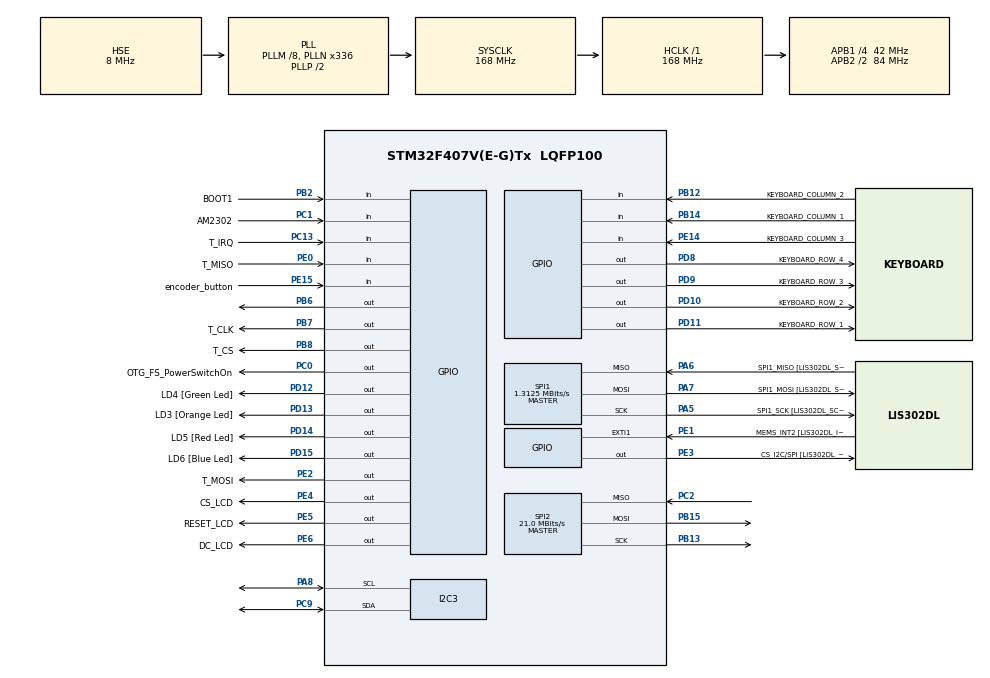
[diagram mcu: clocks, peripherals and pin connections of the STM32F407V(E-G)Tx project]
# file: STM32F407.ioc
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Mcu.Family=STM32F4
Mcu.Name=STM32F407V(E-G)Tx
Mcu.Package=LQFP100
NVIC.PriorityGroup=NVIC_PRIORITYGROUP_0
NVIC.RCC_IRQn=true\:0\:0\:false\:false\:true\:true\:false
NVIC.TIM1_CC_IRQn=true\:0\:0\:false\:false\:true\:true\:true
PA11.GPIO_Label=OTG_FS_DM
PA11.GPIO_Mode=GPIO_MODE_AF_PP
PA11.GPIO_PuPd=GPIO_NOPULL
PA11.GPIO_Speed=GPIO_SPEED_FREQ_LOW
PA11.Signal=USB_OTG_FS_DM
PA13.GPIO_Label=SWDIO
PA13.Mode=Serial_Wire
PA13.Signal=SYS_JTMS-SWDIO
PA14.GPIO_Label=SWCLK
PA14.Mode=Serial_Wire
PA14.Signal=SYS_JTCK-SWCLK
PA4.GPIO_Label=I2S3_WS [CS43L22_LRCK]
PA4.GPIO_Mode=GPIO_MODE_AF_PP
PA4.GPIO_PuPd=GPIO_NOPULL
PA4.GPIO_Speed=GPIO_SPEED_FREQ_LOW
PA4.Signal=I2S3_WS
PA5.GPIO_Label=SPI1_SCK [LIS302DL_SCL/SPC]
PA5.GPIO_Mode=GPIO_MODE_AF_PP
PA5.GPIO_PuPd=GPIO_NOPULL
PA5.GPIO_Speed=GPIO_SPEED_FREQ_VERY_HIGH
PA5.Mode=Full_Duplex_Master
PA5.Signal=SPI1_SCK
PA6.GPIO_Label=SPI1_MISO [LIS302DL_SDO]
PA6.GPIO_Mode=GPIO_MODE_AF_PP
PA6.GPIO_PuPd=GPIO_NOPULL
PA6.GPIO_Speed=GPIO_SPEED_FREQ_VERY_HIGH
PA6.Mode=Full_Duplex_Master
PA6.Signal=SPI1_MISO
PA7.GPIO_Label=SPI1_MOSI [LIS302DL_SDA/SDI/SDO]
PA7.GPIO_Mode=GPIO_MODE_AF_PP
PA7.GPIO_PuPd=GPIO_NOPULL
PA7.GPIO_Speed=GPIO_SPEED_FREQ_VERY_HIGH
PA7.Mode=Full_Duplex_Master
PA7.Signal=SPI1_MOSI
PA8.Mode=I2C
PA8.Signal=I2C3_SCL
PA9.GPIO_Label=VBUS_FS
PA9.GPIO_Mode=GPIO_MODE_INPUT
PA9.GPIO_PuPd=GPIO_NOPULL
PA9.Signal=USB_OTG_FS_VBUS
PB12.GPIO_Label=KEYBOARD_COLUMN_2
PB12.GPIO_PuPd=GPIO_PULLUP
PB12.Signal=GPIO_Input
PB13.Mode=Full_Duplex_Master
PB13.Signal=SPI2_SCK
PB14.GPIO_Label=KEYBOARD_COLUMN_1
PB14.GPIO_PuPd=GPIO_PULLUP
PB14.Signal=GPIO_Input
PB15.Mode=Full_Duplex_Master
PB15.Signal=SPI2_MOSI
PB2.GPIO_Label=BOOT1
PB2.GPIO_Mode=GPIO_MODE_INPUT
PB2.GPIO_PuPd=GPIO_NOPULL
PB2.Signal=GPIO_Input
PB3.GPIO_Label=SWO
PB3.Signal=SYS_JTDO-SWO
PB6.Signal=GPIO_Output
PB7.GPIO_Label=T_CLK
PB7.GPIO_Speed=GPIO_SPEED_FREQ_VERY_HIGH
PB7.Signal=GPIO_Output
PB8.GPIO_Label=T_CS
PB8.GPIO_Speed=GPIO_SPEED_FREQ_VERY_HIGH
PB8.Signal=GPIO_Output
PB9.GPIO_Label=Audio_SDA [CS43L22_SDA]
PB9.GPIO_Mode=GPIO_MODE_AF_OD
PB9.GPIO_PuPd=GPIO_NOPULL
PB9.GPIO_Speed=GPIO_SPEED_FREQ_LOW
PB9.Signal=I2C1_SDA
PC0.GPIO_Label=OTG_FS_PowerSwitchOn
PC0.GPIO_PuPd=GPIO_NOPULL
PC0.GPIO_Speed=GPIO_SPEED_FREQ_LOW
PC0.PinState=GPIO_PIN_SET
PC0.Signal=GPIO_Output
PC1.GPIO_Label=AM2302
PC1.Signal=GPIO_Input
PC13-ANTI_TAMP.GPIO_Label=T_IRQ
PC13-ANTI_TAMP.Signal=GPIO_Input
PC14-OSC32_IN.GPIO_Label=PC14-OSC32_IN
PC14-OSC32_IN.Mode=LSE-External-Oscillator
PC14-OSC32_IN.Signal=RCC_OSC32_IN
PC15-OSC32_OUT.GPIO_Label=PC15-OSC32_OUT
PC15-OSC32_OUT.Mode=LSE-External-Oscillator
PC15-OSC32_OUT.Signal=RCC_OSC32_OUT
PC2.Mode=Full_Duplex_Master
PC2.Signal=SPI2_MISO
PC3.GPIO_Label=PDM_OUT [MP45DT02_DOUT]
PC3.GPIO_Mode=GPIO_MODE_AF_PP
PC3.GPIO_PuPd=GPIO_NOPULL
PC3.GPIO_Speed=GPIO_SPEED_FREQ_LOW
PC3.Signal=I2S2_SD
PC9.Mode=I2C
PC9.Signal=I2C3_SDA
PD10.GPIO_Label=KEYBOARD_ROW_2
PD10.PinState=GPIO_PIN_RESET
PD10.Signal=GPIO_Output
PD11.GPIO_Label=KEYBOARD_ROW_1
PD11.PinState=GPIO_PIN_RESET
PD11.Signal=GPIO_Output
PD12.GPIO_Label=LD4 [Green Led]
PD12.GPIO_PuPd=GPIO_NOPULL
PD12.GPIO_Speed=GPIO_SPEED_FREQ_LOW
PD12.Signal=GPIO_Output
PD13.GPIO_Label=LD3 [Orange Led]
PD13.GPIO_PuPd=GPIO_NOPULL
PD13.GPIO_Speed=GPIO_SPEED_FREQ_LOW
PD13.Signal=GPIO_Output
PD14.GPIO_Label=LD5 [Red Led]
PD14.GPIO_PuPd=GPIO_NOPULL
PD14.GPIO_Speed=GPIO_SPEED_FREQ_LOW
PD14.Signal=GPIO_Output
PD15.GPIO_Label=LD6 [Blue Led]
PD15.GPIO_PuPd=GPIO_NOPULL
PD15.GPIO_Speed=GPIO_SPEED_FREQ_LOW
PD15.Signal=GPIO_Output
PD8.GPIO_Label=KEYBOARD_ROW_4
PD8.PinState=GPIO_PIN_RESET
PD8.Signal=GPIO_Output
PD9.GPIO_Label=KEYBOARD_ROW_3
PD9.PinState=GPIO_PIN_RESET
PD9.Signal=GPIO_Output
PE0.GPIO_Label=T_MISO
PE0.GPIO_PuPd=GPIO_NOPULL
PE0.Signal=GPIO_Input
PE1.GPIO_Label=MEMS_INT2 [LIS302DL_INT2]
PE1.GPIO_ModeDefaultEXTI=GPIO_MODE_EVT_RISING
PE1.GPIO_PuPd=GPIO_NOPULL
PE1.Signal=GPXTI1
PE14.GPIO_Label=KEYBOARD_COLUMN_3
PE14.GPIO_PuPd=GPIO_PULLUP
PE14.Signal=GPIO_Input
PE15.GPIO_Label=encoder_button
PE15.GPIO_PuPd=GPIO_PULLUP
PE15.Signal=GPIO_Input
PE2.GPIO_Label=T_MOSI
PE2.GPIO_Speed=GPIO_SPEED_FREQ_VERY_HIGH
PE2.Signal=GPIO_Output
PE3.GPIO_Label=CS_I2C/SPI [LIS302DL_CS_I2C/SPI]
PE3.GPIO_PuPd=GPIO_NOPULL
PE3.GPIO_Speed=GPIO_SPEED_FREQ_LOW
PE3.Signal=GPIO_Output
PE4.GPIO_Label=CS_LCD
PE4.GPIO_Speed=GPIO_SPEED_FREQ_VERY_HIGH
PE4.Signal=GPIO_Output
PE5.GPIO_Label=RESET_LCD
PE5.GPIO_Speed=GPIO_SPEED_FREQ_VERY_HIGH
PE5.Signal=GPIO_Output
PE6.GPIO_Label=DC_LCD
PE6.GPIO_Speed=GPIO_SPEED_FREQ_VERY_HIGH
PE6.Signal=GPIO_Output
PH0-OSC_IN.GPIO_Label=PH0-OSC_IN
PH0-OSC_IN.Mode=HSE-External-Oscillator
PH0-OSC_IN.Signal=RCC_OSC_IN
PH1-OSC_OUT.GPIO_Label=PH1-OSC_OUT
PH1-OSC_OUT.Mode=HSE-External-Oscillator
PH1-OSC_OUT.Signal=RCC_OSC_OUT
ProjectManager.HeapSize=0x200
ProjectManager.StackSize=0x400
ProjectManager.TargetToolchain=STM32CubeIDE
RCC.48MHZClocksFreq_Value=48000000
RCC.AHBFreq_Value=168000000
RCC.APB1CLKDivider=RCC_HCLK_DIV4
RCC.APB1Freq_Value=42000000
RCC.APB1TimFreq_Value=84000000
RCC.APB2CLKDivider=RCC_HCLK_DIV2
RCC.APB2Freq_Value=84000000
RCC.APB2TimFreq_Value=168000000
RCC.CortexFreq_Value=168000000
RCC.HCLKFreq_Value=168000000
RCC.HSE_VALUE=8000000
RCC.HSI_VALUE=16000000
RCC.PLLM=8
RCC.PLLN=336
RCC.PLLQ=7
RCC.PLLSourceVirtual=RCC_PLLSOURCE_HSE
RCC.SYSCLKFreq_VALUE=168000000
RCC.SYSCLKSource=RCC_SYSCLKSOURCE_PLLCLK
RCC.VCOOutputFreq_Value=336000000
SPI1.BaudRatePrescaler=SPI_BAUDRATEPRESCALER_64
SPI1.BaudRatePrescaler-Full_Duplex_Master=SPI_BAUDRATEPRESCALER_2
SPI1.CalculateBaudRate=1.3125 MBits/s
SPI1.CalculateBaudRate-Full_Duplex_Master=42.0 MBits/s
SPI1.Direction=SPI_DIRECTION_2LINES
SPI1.Mode=SPI_MODE_MASTER
SPI1.Mode-Full_Duplex_Master=SPI_MODE_MASTER
SPI1.VirtualType=VM_MASTER
SPI2.CalculateBaudRate=21.0 MBits/s
SPI2.Direction=SPI_DIRECTION_2LINES
SPI2.Mode=SPI_MODE_MASTER
SPI2.VirtualType=VM_MASTER
TIM1.AutoReloadPreload=TIM_AUTORELOAD_PRELOAD_ENABLE
TIM1.Channel-Output\ Compare1\ No\ Output=TIM_CHANNEL_1
TIM1.Period=10000
TIM1.Prescaler=16800
TIM1.TIM_MasterOutputTrigger=TIM_TRGO_ENABLE
VP_RNG_VS_RNG.Mode=RNG_Activate
VP_TIM1_VS_no_output1.Mode=Output Compare1 No Output
board=STM32F407G-DISC1

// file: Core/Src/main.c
/* USER CODE BEGIN Header */
/**
  ******************************************************************************
  * @file           : main.c
  * @brief          : Main program body
  ******************************************************************************
  * @attention
  *
  * <h2><center>&copy; Copyright (c) 2021 STMicroelectronics.
  * All rights reserved.</center></h2>
  *
  * This software component is licensed by ST under Ultimate Liberty license
  * SLA0044, the "License"; You may not use this file except in compliance with
  * the License. You may obtain a copy of the License at:
  *                             www.st.com/SLA0044
  *
  *///
/* USER CODE END Header */
#include "main.h"

/* USER CODE BEGIN Includes */
#include "screens/lcd/ILI9341_Touchscreen.h"
#include "screens/lcd/ILI9341_STM32_Driver.h"
#include "screens/lcd/ILI9341_GFX.h"
#include "screens/lcd/LCD.h"

#include <stdbool.h>

/* USER CODE END Includes */

I2C_HandleTypeDef hi2c3;

RNG_HandleTypeDef hrng;

SPI_HandleTypeDef hspi1;
SPI_HandleTypeDef hspi2;

TIM_HandleTypeDef htim1;

void SystemClock_Config(void);
static void MX_GPIO_Init(void);
static void MX_SPI1_Init(void);
static void MX_SPI2_Init(void);
static void MX_RNG_Init(void);
static void MX_TIM1_Init(void);
static void MX_I2C3_Init(void);

int main(void)
{

  /* MCU Configuration--------------------------------------------------------*/

  /* Reset of all peripherals, Initializes the Flash interface and the Systick. */
  HAL_Init();

  /* Configure the system clock */
  SystemClock_Config();

  /* Initialize all configured peripherals */
  MX_GPIO_Init();
  MX_SPI1_Init();
  MX_SPI2_Init();
  MX_RNG_Init();
  MX_TIM1_Init();
  MX_I2C3_Init();

  /* Infinite loop */
  /* USER CODE BEGIN WHILE */
  // Turn on TIM 1
  // Start blink GREEN LED
  HAL_TIM_OC_Start_IT(&htim1, TIM_CHANNEL_1);

  // Init LCD
  ILI9341_Init();
  ILI9341_Fill_Screen(BLACK);
  ILI9341_Set_Rotation(SCREEN_HORIZONTAL_2);

  ILI9341_Fill_Screen(BLACK);
  int number_of_tests = 150;
  speed_test_LCD(number_of_tests);
  ILI9341_Fill_Screen(BLACK);

  while (1)
  {

	  // Keyboard test //////////////////////////////////////////////
//	  if(keyboard.read_one_digit_status == true)
//	  {
//		  ILI9341_Draw_Text( keyboard.keyboard_digits_buffer, 10, 10, WHITE, 3, BLACK);
//	  }
	  /////////////////////////////////////////////////////////////////

    /* USER CODE END WHILE */

  }
}

void SystemClock_Config(void)
{
  RCC_OscInitTypeDef RCC_OscInitStruct = {0};
  RCC_ClkInitTypeDef RCC_ClkInitStruct = {0};

  /** Configure the main internal regulator output voltage
  */
  __HAL_RCC_PWR_CLK_ENABLE();
  __HAL_PWR_VOLTAGESCALING_CONFIG(PWR_REGULATOR_VOLTAGE_SCALE1);
  /** Initializes the RCC Oscillators according to the specified parameters
  * in the RCC_OscInitTypeDef structure.
  */
  RCC_OscInitStruct.OscillatorType = RCC_OSCILLATORTYPE_HSE;
  RCC_OscInitStruct.HSEState = RCC_HSE_ON;
  RCC_OscInitStruct.PLL.PLLState = RCC_PLL_ON;
  RCC_OscInitStruct.PLL.PLLSource = RCC_PLLSOURCE_HSE;
  RCC_OscInitStruct.PLL.PLLM = 8;
  RCC_OscInitStruct.PLL.PLLN = 336;
  RCC_OscInitStruct.PLL.PLLP = RCC_PLLP_DIV2;
  RCC_OscInitStruct.PLL.PLLQ = 7;
  if (HAL_RCC_OscConfig(&RCC_OscInitStruct) != HAL_OK)
  {
    Error_Handler();
  }
  /** Initializes the CPU, AHB and APB buses clocks
  */
  RCC_ClkInitStruct.ClockType = RCC_CLOCKTYPE_HCLK|RCC_CLOCKTYPE_SYSCLK
                              |RCC_CLOCKTYPE_PCLK1|RCC_CLOCKTYPE_PCLK2;
  RCC_ClkInitStruct.SYSCLKSource = RCC_SYSCLKSOURCE_PLLCLK;
  RCC_ClkInitStruct.AHBCLKDivider = RCC_SYSCLK_DIV1;
  RCC_ClkInitStruct.APB1CLKDivider = RCC_HCLK_DIV4;
  RCC_ClkInitStruct.APB2CLKDivider = RCC_HCLK_DIV2;

  if (HAL_RCC_ClockConfig(&RCC_ClkInitStruct, FLASH_LATENCY_5) != HAL_OK)
  {
    Error_Handler();
  }
}

static void MX_I2C3_Init(void)
{

  hi2c3.Instance = I2C3;
  hi2c3.Init.ClockSpeed = 100000;
  hi2c3.Init.DutyCycle = I2C_DUTYCYCLE_2;
  hi2c3.Init.OwnAddress1 = 0;
  hi2c3.Init.AddressingMode = I2C_ADDRESSINGMODE_7BIT;
  hi2c3.Init.DualAddressMode = I2C_DUALADDRESS_DISABLE;
  hi2c3.Init.OwnAddress2 = 0;
  hi2c3.Init.GeneralCallMode = I2C_GENERALCALL_DISABLE;
  hi2c3.Init.NoStretchMode = I2C_NOSTRETCH_DISABLE;
  if (HAL_I2C_Init(&hi2c3) != HAL_OK)
  {
    Error_Handler();
  }

}

static void MX_RNG_Init(void)
{

  hrng.Instance = RNG;
  if (HAL_RNG_Init(&hrng) != HAL_OK)
  {
    Error_Handler();
  }

}

static void MX_SPI1_Init(void)
{

  /* SPI1 parameter configuration*/
  hspi1.Instance = SPI1;
  hspi1.Init.Mode = SPI_MODE_MASTER;
  hspi1.Init.Direction = SPI_DIRECTION_2LINES;
  hspi1.Init.DataSize = SPI_DATASIZE_8BIT;
  hspi1.Init.CLKPolarity = SPI_POLARITY_LOW;
  hspi1.Init.CLKPhase = SPI_PHASE_1EDGE;
  hspi1.Init.NSS = SPI_NSS_SOFT;
  hspi1.Init.BaudRatePrescaler = SPI_BAUDRATEPRESCALER_64;
  hspi1.Init.FirstBit = SPI_FIRSTBIT_MSB;
  hspi1.Init.TIMode = SPI_TIMODE_DISABLE;
  hspi1.Init.CRCCalculation = SPI_CRCCALCULATION_DISABLE;
  hspi1.Init.CRCPolynomial = 10;
  if (HAL_SPI_Init(&hspi1) != HAL_OK)
  {
    Error_Handler();
  }

}

static void MX_SPI2_Init(void)
{

  /* SPI2 parameter configuration*/
  hspi2.Instance = SPI2;
  hspi2.Init.Mode = SPI_MODE_MASTER;
  hspi2.Init.Direction = SPI_DIRECTION_2LINES;
  hspi2.Init.DataSize = SPI_DATASIZE_8BIT;
  hspi2.Init.CLKPolarity = SPI_POLARITY_LOW;
  hspi2.Init.CLKPhase = SPI_PHASE_1EDGE;
  hspi2.Init.NSS = SPI_NSS_SOFT;
  hspi2.Init.BaudRatePrescaler = SPI_BAUDRATEPRESCALER_2;
  hspi2.Init.FirstBit = SPI_FIRSTBIT_MSB;
  hspi2.Init.TIMode = SPI_TIMODE_DISABLE;
  hspi2.Init.CRCCalculation = SPI_CRCCALCULATION_DISABLE;
  hspi2.Init.CRCPolynomial = 10;
  if (HAL_SPI_Init(&hspi2) != HAL_OK)
  {
    Error_Handler();
  }

}

static void MX_TIM1_Init(void)
{

  TIM_MasterConfigTypeDef sMasterConfig = {0};
  TIM_OC_InitTypeDef sConfigOC = {0};
  TIM_BreakDeadTimeConfigTypeDef sBreakDeadTimeConfig = {0};

  htim1.Instance = TIM1;
  htim1.Init.Prescaler = 16800;
  htim1.Init.CounterMode = TIM_COUNTERMODE_UP;
  htim1.Init.Period = 10000;
  htim1.Init.ClockDivision = TIM_CLOCKDIVISION_DIV1;
  htim1.Init.RepetitionCounter = 0;
  htim1.Init.AutoReloadPreload = TIM_AUTORELOAD_PRELOAD_ENABLE;
  if (HAL_TIM_OC_Init(&htim1) != HAL_OK)
  {
    Error_Handler();
  }
  sMasterConfig.MasterOutputTrigger = TIM_TRGO_ENABLE;
  sMasterConfig.MasterSlaveMode = TIM_MASTERSLAVEMODE_DISABLE;
  if (HAL_TIMEx_MasterConfigSynchronization(&htim1, &sMasterConfig) != HAL_OK)
  {
    Error_Handler();
  }
  sConfigOC.OCMode = TIM_OCMODE_TIMING;
  sConfigOC.Pulse = 0;
  sConfigOC.OCPolarity = TIM_OCPOLARITY_HIGH;
  sConfigOC.OCNPolarity = TIM_OCNPOLARITY_HIGH;
  sConfigOC.OCFastMode = TIM_OCFAST_DISABLE;
  sConfigOC.OCIdleState = TIM_OCIDLESTATE_RESET;
  sConfigOC.OCNIdleState = TIM_OCNIDLESTATE_RESET;
  if (HAL_TIM_OC_ConfigChannel(&htim1, &sConfigOC, TIM_CHANNEL_1) != HAL_OK)
  {
    Error_Handler();
  }
  sBreakDeadTimeConfig.OffStateRunMode = TIM_OSSR_DISABLE;
  sBreakDeadTimeConfig.OffStateIDLEMode = TIM_OSSI_DISABLE;
  sBreakDeadTimeConfig.LockLevel = TIM_LOCKLEVEL_OFF;
  sBreakDeadTimeConfig.DeadTime = 0;
  sBreakDeadTimeConfig.BreakState = TIM_BREAK_DISABLE;
  sBreakDeadTimeConfig.BreakPolarity = TIM_BREAKPOLARITY_HIGH;
  sBreakDeadTimeConfig.AutomaticOutput = TIM_AUTOMATICOUTPUT_DISABLE;
  if (HAL_TIMEx_ConfigBreakDeadTime(&htim1, &sBreakDeadTimeConfig) != HAL_OK)
  {
    Error_Handler();
  }

}

static void MX_GPIO_Init(void)
{
  GPIO_InitTypeDef GPIO_InitStruct = {0};

  /* GPIO Ports Clock Enable */
  __HAL_RCC_GPIOE_CLK_ENABLE();
  __HAL_RCC_GPIOC_CLK_ENABLE();
  __HAL_RCC_GPIOH_CLK_ENABLE();
  __HAL_RCC_GPIOA_CLK_ENABLE();
  __HAL_RCC_GPIOB_CLK_ENABLE();
  __HAL_RCC_GPIOD_CLK_ENABLE();

  /*Configure GPIO pin Output Level */
  HAL_GPIO_WritePin(GPIOE, T_MOSI_Pin|CS_I2C_SPI_Pin|CS_LCD_Pin|RESET_LCD_Pin
                          |DC_LCD_Pin, GPIO_PIN_RESET);

  /*Configure GPIO pin Output Level */
  HAL_GPIO_WritePin(OTG_FS_PowerSwitchOn_GPIO_Port, OTG_FS_PowerSwitchOn_Pin, GPIO_PIN_SET);

  /*Configure GPIO pin Output Level */
  HAL_GPIO_WritePin(GPIOD, KEYBOARD_ROW_4_Pin|KEYBOARD_ROW_3_Pin|KEYBOARD_ROW_2_Pin|KEYBOARD_ROW_1_Pin
                          |LD4_Pin|LD3_Pin|LD5_Pin|LD6_Pin, GPIO_PIN_RESET);

  /*Configure GPIO pin Output Level */
  HAL_GPIO_WritePin(GPIOB, GPIO_PIN_6|T_CLK_Pin|T_CS_Pin, GPIO_PIN_RESET);

  /*Configure GPIO pins : T_MOSI_Pin CS_LCD_Pin RESET_LCD_Pin DC_LCD_Pin */
  GPIO_InitStruct.Pin = T_MOSI_Pin|CS_LCD_Pin|RESET_LCD_Pin|DC_LCD_Pin;
  GPIO_InitStruct.Mode = GPIO_MODE_OUTPUT_PP;
  GPIO_InitStruct.Pull = GPIO_NOPULL;
  GPIO_InitStruct.Speed = GPIO_SPEED_FREQ_VERY_HIGH;
  HAL_GPIO_Init(GPIOE, &GPIO_InitStruct);

  /*Configure GPIO pin : CS_I2C_SPI_Pin */
  GPIO_InitStruct.Pin = CS_I2C_SPI_Pin;
  GPIO_InitStruct.Mode = GPIO_MODE_OUTPUT_PP;
  GPIO_InitStruct.Pull = GPIO_NOPULL;
  GPIO_InitStruct.Speed = GPIO_SPEED_FREQ_LOW;
  HAL_GPIO_Init(CS_I2C_SPI_GPIO_Port, &GPIO_InitStruct);

  /*Configure GPIO pins : T_IRQ_Pin AM2302_Pin */
  GPIO_InitStruct.Pin = T_IRQ_Pin|AM2302_Pin;
  GPIO_InitStruct.Mode = GPIO_MODE_INPUT;
  GPIO_InitStruct.Pull = GPIO_NOPULL;
  HAL_GPIO_Init(GPIOC, &GPIO_InitStruct);

  /*Configure GPIO pin : OTG_FS_PowerSwitchOn_Pin */
  GPIO_InitStruct.Pin = OTG_FS_PowerSwitchOn_Pin;
  GPIO_InitStruct.Mode = GPIO_MODE_OUTPUT_PP;
  GPIO_InitStruct.Pull = GPIO_NOPULL;
  GPIO_InitStruct.Speed = GPIO_SPEED_FREQ_LOW;
  HAL_GPIO_Init(OTG_FS_PowerSwitchOn_GPIO_Port, &GPIO_InitStruct);

  /*Configure GPIO pin : PDM_OUT_Pin */
  GPIO_InitStruct.Pin = PDM_OUT_Pin;
  GPIO_InitStruct.Mode = GPIO_MODE_AF_PP;
  GPIO_InitStruct.Pull = GPIO_NOPULL;
  GPIO_InitStruct.Speed = GPIO_SPEED_FREQ_LOW;
  GPIO_InitStruct.Alternate = GPIO_AF5_SPI2;
  HAL_GPIO_Init(PDM_OUT_GPIO_Port, &GPIO_InitStruct);

  /*Configure GPIO pin : I2S3_WS_Pin */
  GPIO_InitStruct.Pin = I2S3_WS_Pin;
  GPIO_InitStruct.Mode = GPIO_MODE_AF_PP;
  GPIO_InitStruct.Pull = GPIO_NOPULL;
  GPIO_InitStruct.Speed = GPIO_SPEED_FREQ_LOW;
  GPIO_InitStruct.Alternate = GPIO_AF6_SPI3;
  HAL_GPIO_Init(I2S3_WS_GPIO_Port, &GPIO_InitStruct);

  /*Configure GPIO pin : BOOT1_Pin */
  GPIO_InitStruct.Pin = BOOT1_Pin;
  GPIO_InitStruct.Mode = GPIO_MODE_INPUT;
  GPIO_InitStruct.Pull = GPIO_NOPULL;
  HAL_GPIO_Init(BOOT1_GPIO_Port, &GPIO_InitStruct);

  /*Configure GPIO pins : KEYBOARD_COLUMN_3_Pin encoder_button_Pin */
  GPIO_InitStruct.Pin = KEYBOARD_COLUMN_3_Pin|encoder_button_Pin;
  GPIO_InitStruct.Mode = GPIO_MODE_INPUT;
  GPIO_InitStruct.Pull = GPIO_PULLUP;
  HAL_GPIO_Init(GPIOE, &GPIO_InitStruct);

  /*Configure GPIO pins : KEYBOARD_COLUMN_2_Pin KEYBOARD_COLUMN_1_Pin */
  GPIO_InitStruct.Pin = KEYBOARD_COLUMN_2_Pin|KEYBOARD_COLUMN_1_Pin;
  GPIO_InitStruct.Mode = GPIO_MODE_INPUT;
  GPIO_InitStruct.Pull = GPIO_PULLUP;
  HAL_GPIO_Init(GPIOB, &GPIO_InitStruct);

  /*Configure GPIO pins : KEYBOARD_ROW_4_Pin KEYBOARD_ROW_3_Pin KEYBOARD_ROW_2_Pin KEYBOARD_ROW_1_Pin
                           LD4_Pin LD3_Pin LD5_Pin LD6_Pin */
  GPIO_InitStruct.Pin = KEYBOARD_ROW_4_Pin|KEYBOARD_ROW_3_Pin|KEYBOARD_ROW_2_Pin|KEYBOARD_ROW_1_Pin
                          |LD4_Pin|LD3_Pin|LD5_Pin|LD6_Pin;
  GPIO_InitStruct.Mode = GPIO_MODE_OUTPUT_PP;
  GPIO_InitStruct.Pull = GPIO_NOPULL;
  GPIO_InitStruct.Speed = GPIO_SPEED_FREQ_LOW;
  HAL_GPIO_Init(GPIOD, &GPIO_InitStruct);

  /*Configure GPIO pin : VBUS_FS_Pin */
  GPIO_InitStruct.Pin = VBUS_FS_Pin;
  GPIO_InitStruct.Mode = GPIO_MODE_INPUT;
  GPIO_InitStruct.Pull = GPIO_NOPULL;
  HAL_GPIO_Init(VBUS_FS_GPIO_Port, &GPIO_InitStruct);

  /*Configure GPIO pin : OTG_FS_DM_Pin */
  GPIO_InitStruct.Pin = OTG_FS_DM_Pin;
  GPIO_InitStruct.Mode = GPIO_MODE_AF_PP;
  GPIO_InitStruct.Pull = GPIO_NOPULL;
  GPIO_InitStruct.Speed = GPIO_SPEED_FREQ_LOW;
  GPIO_InitStruct.Alternate = GPIO_AF10_OTG_FS;
  HAL_GPIO_Init(OTG_FS_DM_GPIO_Port, &GPIO_InitStruct);

  /*Configure GPIO pin : PB6 */
  GPIO_InitStruct.Pin = GPIO_PIN_6;
  GPIO_InitStruct.Mode = GPIO_MODE_OUTPUT_PP;
  GPIO_InitStruct.Pull = GPIO_NOPULL;
  GPIO_InitStruct.Speed = GPIO_SPEED_FREQ_LOW;
  HAL_GPIO_Init(GPIOB, &GPIO_InitStruct);

  /*Configure GPIO pins : T_CLK_Pin T_CS_Pin */
  GPIO_InitStruct.Pin = T_CLK_Pin|T_CS_Pin;
  GPIO_InitStruct.Mode = GPIO_MODE_OUTPUT_PP;
  GPIO_InitStruct.Pull = GPIO_NOPULL;
  GPIO_InitStruct.Speed = GPIO_SPEED_FREQ_VERY_HIGH;
  HAL_GPIO_Init(GPIOB, &GPIO_InitStruct);

  /*Configure GPIO pin : Audio_SDA_Pin */
  GPIO_InitStruct.Pin = Audio_SDA_Pin;
  GPIO_InitStruct.Mode = GPIO_MODE_AF_OD;
  GPIO_InitStruct.Pull = GPIO_PULLUP;
  GPIO_InitStruct.Speed = GPIO_SPEED_FREQ_LOW;
  GPIO_InitStruct.Alternate = GPIO_AF4_I2C1;
  HAL_GPIO_Init(Audio_SDA_GPIO_Port, &GPIO_InitStruct);

  /*Configure GPIO pin : T_MISO_Pin */
  GPIO_InitStruct.Pin = T_MISO_Pin;
  GPIO_InitStruct.Mode = GPIO_MODE_INPUT;
  GPIO_InitStruct.Pull = GPIO_NOPULL;
  HAL_GPIO_Init(T_MISO_GPIO_Port, &GPIO_InitStruct);

  /*Configure GPIO pin : MEMS_INT2_Pin */
  GPIO_InitStruct.Pin = MEMS_INT2_Pin;
  GPIO_InitStruct.Mode = GPIO_MODE_EVT_RISING;
  GPIO_InitStruct.Pull = GPIO_NOPULL;
  HAL_GPIO_Init(MEMS_INT2_GPIO_Port, &GPIO_InitStruct);

}

void Error_Handler(void)
{
  __disable_irq();
  while (1)
  {
  }
}

/************************ (C) COPYRIGHT STMicroelectronics *****END OF FILE****/
